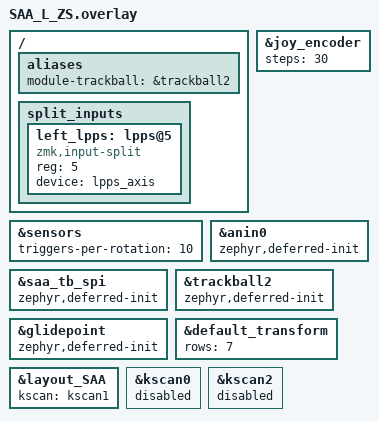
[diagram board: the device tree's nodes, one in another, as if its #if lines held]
#include "SAA_pins.dtsi"
#include "SAA_zs_devices.dtsi"
#define left_encoder module_encoder
#include "SAA_L_ENC.overlay"
#undef left_encoder
#define left_encoder joy_encoder
#include "SAA_L_JOY.overlay"
#undef left_encoder
#include "SAA_L_TB.overlay"
#ifdef SAA_SIM_TWI
#define TPD_BUS i2c0
#else
#define TPD_BUS tpd_bus
#endif
#include "SAA_L_tpd_device.dtsi"
#undef TPD_BUS

/ { aliases { module-trackball = &trackball2; }; };
&sensors { triggers-per-rotation = <10>; };
&joy_encoder { steps = <30>; };
&anin0 { zephyr,deferred-init; };
&saa_tb_spi { zephyr,deferred-init; };
&trackball2 { zephyr,deferred-init; };
&glidepoint { zephyr,deferred-init; };
&default_transform { rows = <7>; };
&layout_SAA { kscan = <&kscan1>; };
&kscan0 { status = "disabled"; };
&kscan2 { status = "disabled"; };

#include "zeroshift_dial.dtsi"
#include "zeroshift_lpps.dtsi"
/ {
    split_inputs { left_lpps: lpps@5 { compatible = "zmk,input-split"; reg = <5>; }; };
};
&left_lpps { device = <&lpps_axis>; };
